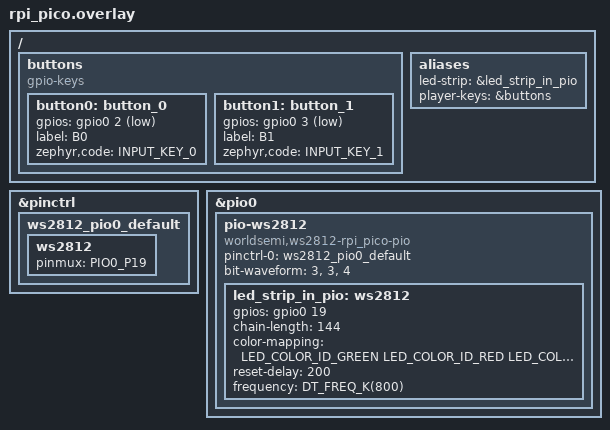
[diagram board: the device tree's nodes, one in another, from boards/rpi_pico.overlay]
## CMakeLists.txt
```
cmake_minimum_required(VERSION 3.20.5)

find_package(Zephyr REQUIRED HINTS $ENV{ZEPHYR_BASE})
project(light)

FILE(GLOB app_sources src/*.c)
target_sources(app PRIVATE ${app_sources})
include_directories(app PRIVATE inc)
```

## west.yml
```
manifest:
  remotes:
    - name: zephyrproject-rtos
      url-base: https://github.com/zephyrproject-rtos
  
  projects:
    - name: zephyr
      remote: zephyrproject-rtos
      revision: v4.3.0
      import:
        name-allowlist:
          - cmsis
          - cmsis_6
          - mbedtls
          - tinycrypt
          - hal_rpi_pico
```

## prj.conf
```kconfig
CONFIG_LED_STRIP=y
CONFIG_INPUT=y
CONFIG_EVENTS=y
```

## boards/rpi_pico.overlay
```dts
#include <zephyr/dt-bindings/led/led.h>
#include <zephyr/dt-bindings/input/input-event-codes.h>
#include <zephyr/dt-bindings/pinctrl/rpi-pico-rp2040-pinctrl.h>

&pinctrl {
    ws2812_pio0_default: ws2812_pio0_default {
        ws2812 {
            pinmux = <PIO0_P19>;
        };
    };
};

&pio0 {
    status = "okay";

    pio-ws2812 {
        compatible = "worldsemi,ws2812-rpi_pico-pio";
        status = "okay";
        pinctrl-0 = <&ws2812_pio0_default>;
        pinctrl-names = "default";
        bit-waveform = <3>, <3>, <4>;
        led_strip_in_pio: ws2812 {
            status = "okay";
            gpios = <&gpio0 19 GPIO_ACTIVE_HIGH>;
            chain-length = <144>;
            color-mapping = <LED_COLOR_ID_GREEN LED_COLOR_ID_RED LED_COLOR_ID_BLUE>;
            reset-delay = <200>;
            frequency = <DT_FREQ_K(800)>;
        };
    };
};

/ {
    buttons: buttons {
        compatible = "gpio-keys";

        button0: button_0 {
            gpios = <&gpio0 2 (GPIO_PULL_UP | GPIO_ACTIVE_LOW)>;
            label = "B0";
            zephyr,code = <INPUT_KEY_0>;
        };

        button1: button_1 {
            gpios = <&gpio0 3 (GPIO_PULL_UP | GPIO_ACTIVE_LOW)>;
            label = "B1";
            zephyr,code = <INPUT_KEY_1>;
        };
    };
};

/ {
    aliases {
        led-strip = &led_strip_in_pio;
		player-keys = &buttons;
    };
};
```

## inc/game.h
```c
/*
 * Copyright 2026 Pedro Zawadniak
 *
 *  Licensed under the Apache License, Version 2.0 (the "License");
 *  you may not use this file except in compliance with the License.
 *  You may obtain a copy of the License at
 *
 *      http://www.apache.org/licenses/LICENSE-2.0
 *
 *  Unless required by applicable law or agreed to in writing, software
 *  distributed under the License is distributed on an "AS IS" BASIS,
 *  WITHOUT WARRANTIES OR CONDITIONS OF ANY KIND, either express or implied.
 *  See the License for the specific language governing permissions and
 *  limitations under the License.
 */

#ifndef GAME_H
#define GAME_H

#include <zephyr/device.h>
#include <zephyr/drivers/gpio.h>

#include <stdint.h>
#include <stdbool.h>

typedef enum {
    GAME_EVT_TICK,
    GAME_EVT_BTN_PLAYER1,
    GAME_EVT_BTN_PLAYER2
} game_evt_type_t;

typedef struct {
    game_evt_type_t type;
} game_evt_t;

typedef struct {
    int32_t paddle_start;
    int32_t paddle_end;
} paddle_pos_t;

typedef struct {
    int32_t min_boundrary;
    int32_t max_boundrary;
    paddle_pos_t p1_paddle;
    paddle_pos_t p2_paddle;
    int32_t ball_pos_after_score;

    int32_t p1_score;
    int32_t p2_score;
    int32_t ball_pos;
    int ball_direction;
} game_state_t;

extern struct k_msgq game_evt_q;

extern struct k_timer game_tick_timer;

void advance_game(game_state_t* game_state);

#endif
```

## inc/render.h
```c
/*
 * Copyright 2026 Pedro Zawadniak
 *
 *  Licensed under the Apache License, Version 2.0 (the "License");
 *  you may not use this file except in compliance with the License.
 *  You may obtain a copy of the License at
 *
 *      http://www.apache.org/licenses/LICENSE-2.0
 *
 *  Unless required by applicable law or agreed to in writing, software
 *  distributed under the License is distributed on an "AS IS" BASIS,
 *  WITHOUT WARRANTIES OR CONDITIONS OF ANY KIND, either express or implied.
 *  See the License for the specific language governing permissions and
 *  limitations under the License.
 */
 
#ifndef RENDER_H
#define RENDER_H

#include "game.h"
#include <zephyr/kernel.h>
#include <zephyr/drivers/led_strip.h>

extern struct k_event render_group_event;

#define RENDER_EVT_ANY 1

extern struct k_mutex render_state_lock;
extern game_state_t render_state;

void draw(game_state_t* render_state, struct led_rgb* pixels, int num_pixels);

#endif
```

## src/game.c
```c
/*
 * Copyright 2026 Pedro Zawadniak
 *
 *  Licensed under the Apache License, Version 2.0 (the "License");
 *  you may not use this file except in compliance with the License.
 *  You may obtain a copy of the License at
 *
 *      http://www.apache.org/licenses/LICENSE-2.0
 *
 *  Unless required by applicable law or agreed to in writing, software
 *  distributed under the License is distributed on an "AS IS" BASIS,
 *  WITHOUT WARRANTIES OR CONDITIONS OF ANY KIND, either express or implied.
 *  See the License for the specific language governing permissions and
 *  limitations under the License.
 */

#include "game.h"
#include "render.h"
#include <zephyr/input/input.h>

#define STRIP_NUM_PIXELS DT_PROP(DT_ALIAS(led_strip), chain_length)
#define PADDLE_SIZE (8)
#define GAME_TIMER_DELAY_MS (15)

K_MSGQ_DEFINE(game_evt_q, sizeof(game_evt_t), 20, 1);

static void do_game2render_post(game_state_t* game_state, game_state_t* render_state, struct k_mutex* render_state_lock, struct k_event* render_group_event, uint32_t event)
{
	k_mutex_lock(render_state_lock, K_FOREVER);
	memcpy(render_state, game_state, sizeof(*game_state));
	k_mutex_unlock(render_state_lock);
	k_event_post(render_group_event, event);
}

void advance_game(game_state_t* game_state) {
	int32_t candidate_ball_pos = game_state->ball_pos + (game_state->ball_direction < 0 ? -1 : 1);
	
	if (candidate_ball_pos < game_state->min_boundrary) {
		game_state->p2_score++;
		game_state->ball_pos = game_state->ball_pos_after_score;
		game_state->ball_direction = 1;
	} else if (candidate_ball_pos > game_state->max_boundrary) {
		game_state->p1_score++;
		game_state->ball_pos = game_state->ball_pos_after_score;
		game_state->ball_direction = -1;
	} else {
		game_state->ball_pos = candidate_ball_pos;
	}
	do_game2render_post(game_state, &render_state, &render_state_lock, &render_group_event, RENDER_EVT_ANY);
}

bool is_ball_in_paddle(paddle_pos_t paddle, int32_t ball)
{
	return (paddle.paddle_start <= ball) && (ball <= paddle.paddle_end);
}

static void game_tick_cb(struct k_timer *timer_id)
{
	game_evt_t game_evt = {.type = GAME_EVT_TICK};
	k_msgq_put(&game_evt_q, &game_evt, K_NO_WAIT);
}
K_TIMER_DEFINE(game_tick_timer, game_tick_cb, NULL);

static void game_thread_entrypoint(void*, void*, void*)
{
	game_state_t game_state;
	game_state.ball_pos = STRIP_NUM_PIXELS/2;
	game_state.ball_pos_after_score = STRIP_NUM_PIXELS/2;
	game_state.ball_direction = 1;
	game_state.min_boundrary = 0;
	game_state.max_boundrary = STRIP_NUM_PIXELS - 1;
	game_state.p1_score = 0;
	game_state.p2_score = 0;
	int32_t paddle_size = 8;
	game_state.p1_paddle.paddle_start = 0;
	game_state.p1_paddle.paddle_end = paddle_size;
	game_state.p2_paddle.paddle_start = (STRIP_NUM_PIXELS - 1) - paddle_size;
	game_state.p2_paddle.paddle_end = STRIP_NUM_PIXELS - 1;

	k_timer_start(&game_tick_timer, K_MSEC(GAME_TIMER_DELAY_MS), K_MSEC(GAME_TIMER_DELAY_MS));
	while(1) {
		game_evt_t evt;
		k_msgq_get(&game_evt_q, &evt, K_FOREVER);
		switch(evt.type) {
			case GAME_EVT_BTN_PLAYER1: {
				if (is_ball_in_paddle(game_state.p1_paddle, game_state.ball_pos)) {
					game_state.ball_direction = 1;
				}
			}
			break;
			case GAME_EVT_BTN_PLAYER2: {
				if (is_ball_in_paddle(game_state.p2_paddle, game_state.ball_pos)) {
					game_state.ball_direction = -1;
				}
			}
			break;
			case GAME_EVT_TICK:
				advance_game(&game_state);
			break;
			default:
				break;
		}
	}
}

K_THREAD_DEFINE(game_thread_id,
                4096,
                game_thread_entrypoint,
                NULL, NULL, NULL,
                2,
                0,
                0);


static void paddle_btns_cb(struct input_event* evt, void *user_data)
{
	if (evt->sync == 0) {
		return;
	}
	game_evt_type_t evt_type;
	switch (evt->code) {
		case INPUT_KEY_0:
			if (!evt->value) {
				return;
			}
            evt_type = GAME_EVT_BTN_PLAYER1;
		break;
		case INPUT_KEY_1:
			if (!evt->value) {
				return;
			}
			evt_type = GAME_EVT_BTN_PLAYER2;
		break;
		default:
			return;
		break;
	}
	game_evt_t game_evt = { .type = evt_type};
	k_msgq_put(&game_evt_q, &game_evt, K_NO_WAIT);
}

INPUT_CALLBACK_DEFINE(DEVICE_DT_GET(DT_ALIAS(player_keys)), paddle_btns_cb, NULL);
```

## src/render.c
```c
/*
 * Copyright 2026 Pedro Zawadniak
 *
 *  Licensed under the Apache License, Version 2.0 (the "License");
 *  you may not use this file except in compliance with the License.
 *  You may obtain a copy of the License at
 *
 *      http://www.apache.org/licenses/LICENSE-2.0
 *
 *  Unless required by applicable law or agreed to in writing, software
 *  distributed under the License is distributed on an "AS IS" BASIS,
 *  WITHOUT WARRANTIES OR CONDITIONS OF ANY KIND, either express or implied.
 *  See the License for the specific language governing permissions and
 *  limitations under the License.
 */

#include "render.h"
#include "game.h"
#include <zephyr/kernel.h>
#include <stdint.h>

K_EVENT_DEFINE(render_group_event);

K_MUTEX_DEFINE(render_state_lock);

game_state_t render_state;

#define RGB(_r, _g, _b) { .r = (_r), .g = (_g), .b = (_b) }

#define STRIP_NUM_PIXELS DT_PROP(DT_ALIAS(led_strip), chain_length)
const struct device *const led_strip_dev = DEVICE_DT_GET(DT_ALIAS(led_strip));

static void render_thread_entrypoint(void*, void*, void*)
{
	struct led_rgb pixels[STRIP_NUM_PIXELS];
    memset(pixels, 0, sizeof(pixels));

	while (1) {
        uint32_t evt = k_event_wait_safe(&render_group_event, RENDER_EVT_ANY, true, K_FOREVER);
        k_mutex_lock(&render_state_lock, K_FOREVER);
        game_state_t local_render_state = render_state;
        k_mutex_unlock(&render_state_lock);
        
        if (evt & RENDER_EVT_ANY) {
            memset(pixels, 0, sizeof(pixels));
            draw(&local_render_state, pixels, STRIP_NUM_PIXELS);
            led_strip_update_rgb(led_strip_dev, pixels, STRIP_NUM_PIXELS);
        }
	}
}

void draw(game_state_t* render_state, struct led_rgb* pixels, int num_pixels)
{
    const struct led_rgb paddle_color = RGB(75, 65, 20); 
    const struct led_rgb ball_color = RGB(180, 180, 180);
    for (int i = render_state->p1_paddle.paddle_start; i <= render_state->p1_paddle.paddle_end; i++) {
        pixels[i] = paddle_color;
    }
    for (int i = render_state->p2_paddle.paddle_start; i <= render_state->p2_paddle.paddle_end; i++) {
        pixels[i] = paddle_color;
    }
    pixels[render_state->ball_pos] = ball_color;
}

K_THREAD_DEFINE(render_thread_id,
                2048,
                render_thread_entrypoint,
                NULL, NULL, NULL,
                4,
                0,
                0);
```
